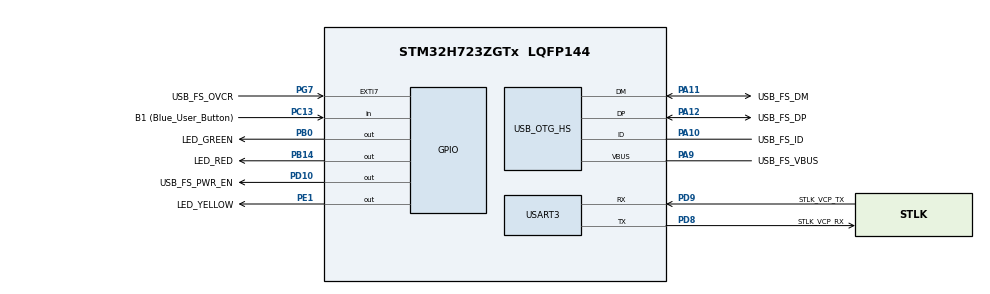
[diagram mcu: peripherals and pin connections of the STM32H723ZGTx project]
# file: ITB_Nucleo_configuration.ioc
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Dma.Request0=USART3_RX
Dma.Request1=USART3_TX
Dma.USART3_RX.0.Direction=DMA_PERIPH_TO_MEMORY
Dma.USART3_RX.0.EventEnable=DISABLE
Dma.USART3_RX.0.FIFOMode=DMA_FIFOMODE_DISABLE
Dma.USART3_RX.0.Instance=DMA1_Stream0
Dma.USART3_RX.0.MemDataAlignment=DMA_MDATAALIGN_BYTE
Dma.USART3_RX.0.MemInc=DMA_MINC_ENABLE
Dma.USART3_RX.0.Mode=DMA_NORMAL
Dma.USART3_RX.0.PeriphDataAlignment=DMA_PDATAALIGN_BYTE
Dma.USART3_RX.0.PeriphInc=DMA_PINC_DISABLE
Dma.USART3_RX.0.Polarity=HAL_DMAMUX_REQ_GEN_RISING
Dma.USART3_RX.0.Priority=DMA_PRIORITY_LOW
Dma.USART3_RX.0.RequestNumber=1
Dma.USART3_RX.0.SignalID=NONE
Dma.USART3_RX.0.SyncEnable=DISABLE
Dma.USART3_RX.0.SyncPolarity=HAL_DMAMUX_SYNC_NO_EVENT
Dma.USART3_RX.0.SyncRequestNumber=1
Dma.USART3_RX.0.SyncSignalID=NONE
Dma.USART3_TX.1.Direction=DMA_MEMORY_TO_PERIPH
Dma.USART3_TX.1.EventEnable=DISABLE
Dma.USART3_TX.1.FIFOMode=DMA_FIFOMODE_DISABLE
Dma.USART3_TX.1.Instance=DMA1_Stream1
Dma.USART3_TX.1.MemDataAlignment=DMA_MDATAALIGN_BYTE
Dma.USART3_TX.1.MemInc=DMA_MINC_ENABLE
Dma.USART3_TX.1.Mode=DMA_NORMAL
Dma.USART3_TX.1.PeriphDataAlignment=DMA_PDATAALIGN_BYTE
Dma.USART3_TX.1.PeriphInc=DMA_PINC_DISABLE
Dma.USART3_TX.1.Polarity=HAL_DMAMUX_REQ_GEN_RISING
Dma.USART3_TX.1.Priority=DMA_PRIORITY_LOW
Dma.USART3_TX.1.RequestNumber=1
Dma.USART3_TX.1.SignalID=NONE
Dma.USART3_TX.1.SyncEnable=DISABLE
Dma.USART3_TX.1.SyncPolarity=HAL_DMAMUX_SYNC_NO_EVENT
Dma.USART3_TX.1.SyncRequestNumber=1
Dma.USART3_TX.1.SyncSignalID=NONE
Mcu.Family=STM32H7
Mcu.Name=STM32H723ZGTx
Mcu.Package=LQFP144
NVIC.DMA1_Stream0_IRQn=true\:0\:0\:false\:false\:true\:false\:true
NVIC.DMA1_Stream1_IRQn=true\:0\:0\:false\:false\:true\:false\:true
NVIC.PriorityGroup=NVIC_PRIORITYGROUP_4
NVIC.TIM6_DAC_IRQn=true\:0\:0\:false\:false\:true\:true\:true
NVIC.USART3_IRQn=true\:0\:0\:false\:false\:true\:true\:true
PA1.GPIO_Label=RMII_REF_CLK
PA1.Signal=ETH_REF_CLK
PA10.GPIO_Label=USB_FS_ID
PA10.Mode=OTG/Dual-Role-Device-FS
PA10.Signal=USB_OTG_HS_ID
PA11.GPIO_Label=USB_FS_DM
PA11.Mode=OTG/Dual-Role-Device-FS
PA11.Signal=USB_OTG_HS_DM
PA12.GPIO_Label=USB_FS_DP
PA12.Mode=OTG/Dual-Role-Device-FS
PA12.Signal=USB_OTG_HS_DP
PA13(JTMS/SWDIO).GPIO_Label=SWDIO
PA13(JTMS/SWDIO).Mode=Trace_Asynchronous_SW
PA13(JTMS/SWDIO).Signal=DEBUG_JTMS-SWDIO
PA14(JTCK/SWCLK).GPIO_Label=SWCLK
PA14(JTCK/SWCLK).Mode=Trace_Asynchronous_SW
PA14(JTCK/SWCLK).Signal=DEBUG_JTCK-SWCLK
PA2.GPIO_Label=RMII_MDIO
PA2.Signal=ETH_MDIO
PA7.GPIO_Label=RMII_CRS_DV
PA7.Signal=ETH_CRS_DV
PA9.GPIO_Label=USB_FS_VBUS
PA9.Mode=Activate_VBUS_FS
PA9.Signal=USB_OTG_HS_VBUS
PB0.GPIO_Label=LED_GREEN
PB0.Signal=GPIO_Output
PB13.GPIO_Label=RMII_TXD1
PB13.Signal=ETH_TXD1
PB14.GPIO_Label=LED_RED
PB14.Signal=GPIO_Output
PB3(JTDO/TRACESWO).GPIO_Label=SWO
PB3(JTDO/TRACESWO).Mode=Trace_Asynchronous_SW
PB3(JTDO/TRACESWO).Signal=DEBUG_JTDO-SWO
PC1.GPIO_Label=RMII_MDC
PC1.Signal=ETH_MDC
PC13.GPIO_Label=B1 (Blue_User_Button)
PC13.Signal=GPIO_Input
PC14-OSC32_IN.Mode=LSE-External-Oscillator
PC14-OSC32_IN.Signal=RCC_OSC32_IN
PC15-OSC32_OUT.Mode=LSE-External-Oscillator
PC15-OSC32_OUT.Signal=RCC_OSC32_OUT
PC4.GPIO_Label=RMII_RXD0
PC4.Signal=ETH_RXD0
PC5.GPIO_Label=RMII_RXD1
PC5.Signal=ETH_RXD1
PD10.GPIO_Label=USB_FS_PWR_EN
PD10.Signal=GPIO_Output
PD8.GPIO_Label=STLK_VCP_RX
PD8.Mode=Asynchronous
PD8.Signal=USART3_TX
PD9.GPIO_Label=STLK_VCP_TX
PD9.Mode=Asynchronous
PD9.Signal=USART3_RX
PE1.GPIO_Label=LED_YELLOW
PE1.Signal=GPIO_Output
PG11.GPIO_Label=RMII_TX_EN
PG11.Signal=ETH_TX_EN
PG13.GPIO_Label=RMII_TXD0
PG13.Signal=ETH_TXD0
PG7.GPIO_Label=USB_FS_OVCR
PG7.Signal=GPXTI7
PH0-OSC_IN.GPIO_Label=MCO
PH0-OSC_IN.Mode=HSE-External-Clock-Source
PH0-OSC_IN.Signal=RCC_OSC_IN
PH1-OSC_OUT.Signal=RCC_OSC_OUT
ProjectManager.HeapSize=0x200
ProjectManager.StackSize=0x400
ProjectManager.TargetToolchain=MDK-ARM V5.27
RCC.ADCFreq_Value=76000000
RCC.APB1Freq_Value=137500000
RCC.APB2Freq_Value=137500000
RCC.APB3Freq_Value=137500000
RCC.APB4Freq_Value=137500000
RCC.CortexFreq_Value=550000000
RCC.D1PPRE=RCC_APB3_DIV2
RCC.D2PPRE1=RCC_APB1_DIV2
RCC.D2PPRE2=RCC_APB2_DIV2
RCC.D3PPRE=RCC_APB4_DIV2
RCC.DIVM1=4
RCC.DIVM2=1
RCC.DIVN1=275
RCC.DIVN2=19
RCC.DIVP1=1
RCC.DIVQ1=4
RCC.HCLKFreq_Value=275000000
RCC.HPRE=RCC_HCLK_DIV2
RCC.HSE_VALUE=8000000
RCC.PLLFRACN=0
RCC.PLLSourceVirtual=RCC_PLLSOURCE_HSE
RCC.SYSCLKFreq_VALUE=550000000
RCC.SYSCLKSource=RCC_SYSCLKSOURCE_PLLCLK
RCC.USBCLockSelection=RCC_USBCLKSOURCE_HSI48
RCC.USBFreq_Value=48000000
TIM6.Period=1000-1
TIM6.Prescaler=275-1
TIM7.Period=32765
TIM7.Prescaler=0
USART3.VirtualMode-Asynchronous=VM_ASYNC
VP_TIM6_VS_ClockSourceINT.Mode=Enable_Timer
VP_TIM7_VS_ClockSourceINT.Mode=Enable_Timer
board=NUCLEO-H723ZG

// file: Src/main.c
/* USER CODE BEGIN Header */
/**
  ******************************************************************************
  * @file           : main.c
  * @brief          : Main program body
  ******************************************************************************
  * @attention
  *
  * <h2><center>&copy; Copyright (c) 2020 STMicroelectronics.
  * All rights reserved.</center></h2>
  *
  * This software component is licensed by ST under BSD 3-Clause license,
  * the "License"; You may not use this file except in compliance with the
  * License. You may obtain a copy of the License at:
  *                        opensource.org/licenses/BSD-3-Clause
  *
  ******************************************************************************
  */
/* USER CODE END Header */
#include "main.h"
#include "dma.h"
#include "tim.h"
#include "usart.h"
#include "usb_otg.h"
#include "gpio.h"

/* USER CODE BEGIN PV */
extern uint8_t RxData[40];
uint32_t Dato1;
/* USER CODE END PV */

void SystemClock_Config(void);

int main(void)
{

  /* MCU Configuration--------------------------------------------------------*/

  /* Reset of all peripherals, Initializes the Flash interface and the Systick. */
  HAL_Init();

  /* Configure the system clock */
  SystemClock_Config();

  /* Initialize all configured peripherals */
  MX_GPIO_Init();
  MX_DMA_Init();
  MX_TIM6_Init();
  MX_TIM7_Init();
  MX_USART3_UART_Init();
  MX_USB_OTG_HS_USB_Init();
  /* USER CODE BEGIN 2 */
	(&huart3)->Instance->CR1|= 0x0010;
	HAL_UART_Receive_IT(&huart3,RxData,40);
	//Dato1=0;
	HAL_TIM_Base_Start_IT(&htim6);
	HAL_TIM_Base_Start(&htim7);
	//INITIALIZE();
  /* USER CODE END 2 */

  /* Infinite loop */
  while (1)
  {

  }
}

void SystemClock_Config(void)
{
  RCC_OscInitTypeDef RCC_OscInitStruct = {0};
  RCC_ClkInitTypeDef RCC_ClkInitStruct = {0};
  RCC_PeriphCLKInitTypeDef PeriphClkInitStruct = {0};

  /** Supply configuration update enable
  */
  HAL_PWREx_ConfigSupply(PWR_LDO_SUPPLY);
  /** Configure the main internal regulator output voltage
  */
  __HAL_PWR_VOLTAGESCALING_CONFIG(PWR_REGULATOR_VOLTAGE_SCALE0);

  while(!__HAL_PWR_GET_FLAG(PWR_FLAG_VOSRDY)) {}
  /** Initializes the RCC Oscillators according to the specified parameters
  * in the RCC_OscInitTypeDef structure.
  */
  RCC_OscInitStruct.OscillatorType = RCC_OSCILLATORTYPE_HSI48|RCC_OSCILLATORTYPE_HSE;
  RCC_OscInitStruct.HSEState = RCC_HSE_BYPASS;
  RCC_OscInitStruct.HSI48State = RCC_HSI48_ON;
  RCC_OscInitStruct.PLL.PLLState = RCC_PLL_ON;
  RCC_OscInitStruct.PLL.PLLSource = RCC_PLLSOURCE_HSE;
  RCC_OscInitStruct.PLL.PLLM = 4;
  RCC_OscInitStruct.PLL.PLLN = 275;
  RCC_OscInitStruct.PLL.PLLP = 1;
  RCC_OscInitStruct.PLL.PLLQ = 4;
  RCC_OscInitStruct.PLL.PLLR = 2;
  RCC_OscInitStruct.PLL.PLLRGE = RCC_PLL1VCIRANGE_1;
  RCC_OscInitStruct.PLL.PLLVCOSEL = RCC_PLL1VCOWIDE;
  RCC_OscInitStruct.PLL.PLLFRACN = 0;
  if (HAL_RCC_OscConfig(&RCC_OscInitStruct) != HAL_OK)
  {
    Error_Handler();
  }
  /** Initializes the CPU, AHB and APB buses clocks
  */
  RCC_ClkInitStruct.ClockType = RCC_CLOCKTYPE_HCLK|RCC_CLOCKTYPE_SYSCLK
                              |RCC_CLOCKTYPE_PCLK1|RCC_CLOCKTYPE_PCLK2
                              |RCC_CLOCKTYPE_D3PCLK1|RCC_CLOCKTYPE_D1PCLK1;
  RCC_ClkInitStruct.SYSCLKSource = RCC_SYSCLKSOURCE_PLLCLK;
  RCC_ClkInitStruct.SYSCLKDivider = RCC_SYSCLK_DIV1;
  RCC_ClkInitStruct.AHBCLKDivider = RCC_HCLK_DIV2;
  RCC_ClkInitStruct.APB3CLKDivider = RCC_APB3_DIV2;
  RCC_ClkInitStruct.APB1CLKDivider = RCC_APB1_DIV2;
  RCC_ClkInitStruct.APB2CLKDivider = RCC_APB2_DIV2;
  RCC_ClkInitStruct.APB4CLKDivider = RCC_APB4_DIV2;

  if (HAL_RCC_ClockConfig(&RCC_ClkInitStruct, FLASH_LATENCY_3) != HAL_OK)
  {
    Error_Handler();
  }
  PeriphClkInitStruct.PeriphClockSelection = RCC_PERIPHCLK_USART3|RCC_PERIPHCLK_USB;
  PeriphClkInitStruct.Usart234578ClockSelection = RCC_USART234578CLKSOURCE_D2PCLK1;
  PeriphClkInitStruct.UsbClockSelection = RCC_USBCLKSOURCE_HSI48;
  if (HAL_RCCEx_PeriphCLKConfig(&PeriphClkInitStruct) != HAL_OK)
  {
    Error_Handler();
  }
  /** Enable USB Voltage detector
  */
  HAL_PWREx_EnableUSBVoltageDetector();
}

void Error_Handler(void)
{
}

/************************ (C) COPYRIGHT STMicroelectronics *****END OF FILE****/
